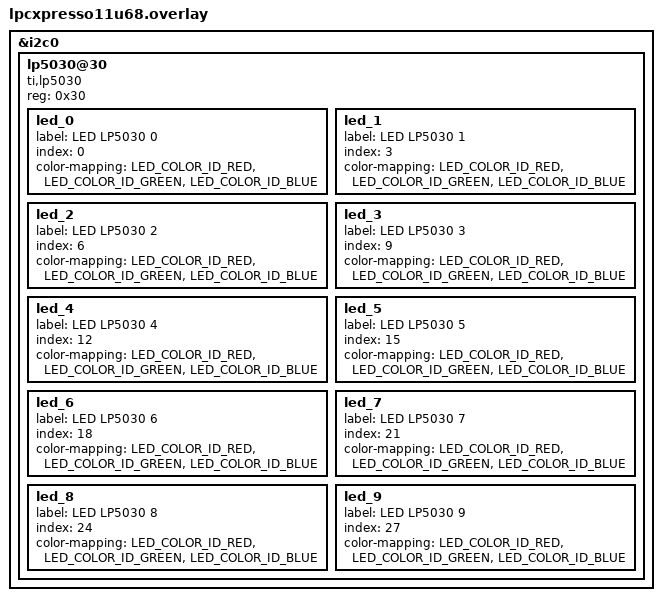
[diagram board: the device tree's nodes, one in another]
/*
 * Copyright (c) 2020 Seagate Technology LLC
 * Copyright (c) 2022 Grinn
 *
 * SPDX-License-Identifier: Apache-2.0
 */

#include <zephyr/dt-bindings/led/led.h>

&i2c0 {
	/* TI LP5030 LED controller connected to I2C0. */
	lp5030@30 {
		compatible = "ti,lp5030";
		reg = <0x30>;

		led_0 {
			label = "LED LP5030 0";
			index = <0>;
			color-mapping =
				<LED_COLOR_ID_RED>,
				<LED_COLOR_ID_GREEN>,
				<LED_COLOR_ID_BLUE>;
		};
		led_1 {
			label = "LED LP5030 1";
			index = <3>;
			color-mapping =
				<LED_COLOR_ID_RED>,
				<LED_COLOR_ID_GREEN>,
				<LED_COLOR_ID_BLUE>;
		};
		led_2 {
			label = "LED LP5030 2";
			index = <6>;
			color-mapping =
				<LED_COLOR_ID_RED>,
				<LED_COLOR_ID_GREEN>,
				<LED_COLOR_ID_BLUE>;
		};
		led_3 {
			label = "LED LP5030 3";
			index = <9>;
			color-mapping =
				<LED_COLOR_ID_RED>,
				<LED_COLOR_ID_GREEN>,
				<LED_COLOR_ID_BLUE>;
		};
		led_4 {
			label = "LED LP5030 4";
			index = <12>;
			color-mapping =
				<LED_COLOR_ID_RED>,
				<LED_COLOR_ID_GREEN>,
				<LED_COLOR_ID_BLUE>;
		};
		led_5 {
			label = "LED LP5030 5";
			index = <15>;
			color-mapping =
				<LED_COLOR_ID_RED>,
				<LED_COLOR_ID_GREEN>,
				<LED_COLOR_ID_BLUE>;
		};
		led_6 {
			label = "LED LP5030 6";
			index = <18>;
			color-mapping =
				<LED_COLOR_ID_RED>,
				<LED_COLOR_ID_GREEN>,
				<LED_COLOR_ID_BLUE>;
		};
		led_7 {
			label = "LED LP5030 7";
			index = <21>;
			color-mapping =
				<LED_COLOR_ID_RED>,
				<LED_COLOR_ID_GREEN>,
				<LED_COLOR_ID_BLUE>;
		};
		led_8 {
			label = "LED LP5030 8";
			index = <24>;
			color-mapping =
				<LED_COLOR_ID_RED>,
				<LED_COLOR_ID_GREEN>,
				<LED_COLOR_ID_BLUE>;
		};
		led_9 {
			label = "LED LP5030 9";
			index = <27>;
			color-mapping =
				<LED_COLOR_ID_RED>,
				<LED_COLOR_ID_GREEN>,
				<LED_COLOR_ID_BLUE>;
		};
	};
};
